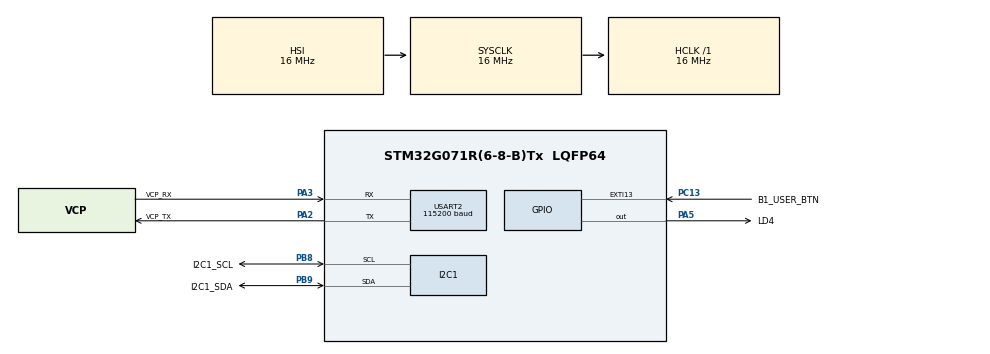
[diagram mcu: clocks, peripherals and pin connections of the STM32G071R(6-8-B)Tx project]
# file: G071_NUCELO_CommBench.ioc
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I2C1.Timing=0x00503D58
Mcu.Family=STM32G0
Mcu.Name=STM32G071R(6-8-B)Tx
Mcu.Package=LQFP64
NVIC.EXTI4_15_IRQn=true\:0\:0\:true\:false\:true\:true\:true\:true
NVIC.I2C1_IRQn=true\:0\:0\:true\:false\:true\:true\:true\:true
NVIC.TIM6_DAC_LPTIM1_IRQn=true\:0\:0\:true\:false\:true\:true\:true\:true
NVIC.USART2_IRQn=true\:0\:0\:true\:false\:true\:true\:true\:true
PA2.GPIO_Label=VCP_TX
PA2.Mode=Asynchronous
PA2.Signal=USART2_TX
PA3.GPIO_Label=VCP_RX
PA3.Mode=Asynchronous
PA3.Signal=USART2_RX
PA5.GPIO_Label=LD4
PA5.Signal=GPIO_Output
PB8.GPIO_Label=I2C1_SCL
PB8.Mode=I2C
PB8.Signal=I2C1_SCL
PB9.GPIO_Label=I2C1_SDA
PB9.Mode=I2C
PB9.Signal=I2C1_SDA
PC13.GPIO_Label=B1_USER_BTN
PC13.GPIO_ModeDefaultEXTI=GPIO_MODE_IT_FALLING
PC13.GPIO_PuPd=GPIO_NOPULL
PC13.Signal=GPXTI13
ProjectManager.HeapSize=0x2000
ProjectManager.StackSize=0x1000
ProjectManager.TargetToolchain=STM32CubeIDE
RCC.AHBFreq_Value=16000000
RCC.CortexFreq_Value=16000000
RCC.EXTERNAL_CLOCK_VALUE=48000
RCC.HCLKFreq_Value=16000000
RCC.HSE_VALUE=8000000
RCC.HSI_VALUE=16000000
RCC.LSE_VALUE=32768
RCC.SYSCLKFreq_VALUE=16000000
RCC.VCOOutputFreq_Value=128000000
TIM6.Period=99
TIM6.Prescaler=15
USART2.BaudRate=115200
USART2.VirtualMode-Asynchronous=VM_ASYNC
USART2.WordLength=WORDLENGTH_8B
VP_TIM6_VS_ClockSourceINT.Mode=Enable_Timer
board=custom

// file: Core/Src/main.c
/* USER CODE BEGIN Header */
/**
  ******************************************************************************
  * @file           : main.c
  * @brief          : Main program body
  ******************************************************************************
  * @attention
  *
  * Copyright (c) 2026 STMicroelectronics.
  * All rights reserved.
  *
  * This software is licensed under terms that can be found in the LICENSE file
  * in the root directory of this software component.
  * If no LICENSE file comes with this software, it is provided AS-IS.
  *
  ******************************************************************************
  */
/* USER CODE END Header */
#include "main.h"

/* USER CODE BEGIN Includes */
#include "global_includes.h"
/* USER CODE END Includes */

I2C_HandleTypeDef hi2c1;

TIM_HandleTypeDef htim6;

UART_HandleTypeDef huart2;

void SystemClock_Config(void);
static void MX_GPIO_Init(void);
static void MX_I2C1_Init(void);
static void MX_USART2_UART_Init(void);
static void MX_TIM6_Init(void);

int main(void)
{

  /* MCU Configuration--------------------------------------------------------*/

  /* Reset of all peripherals, Initializes the Flash interface and the Systick. */
  HAL_Init();

  /* Configure the system clock */
  SystemClock_Config();

  /* Initialize all configured peripherals */
  MX_GPIO_Init();
  MX_I2C1_Init();
  MX_USART2_UART_Init();
  MX_TIM6_Init();
  /* USER CODE BEGIN 2 */
  once();
  /* USER CODE END 2 */

  /* Infinite loop */
  /* USER CODE BEGIN WHILE */
  while (1)
  {
    loop();
    /* USER CODE END WHILE */

  }
}

void SystemClock_Config(void)
{
  RCC_OscInitTypeDef RCC_OscInitStruct = {0};
  RCC_ClkInitTypeDef RCC_ClkInitStruct = {0};

  /** Configure the main internal regulator output voltage
  */
  HAL_PWREx_ControlVoltageScaling(PWR_REGULATOR_VOLTAGE_SCALE1);

  /** Initializes the RCC Oscillators according to the specified parameters
  * in the RCC_OscInitTypeDef structure.
  */
  RCC_OscInitStruct.OscillatorType = RCC_OSCILLATORTYPE_HSI;
  RCC_OscInitStruct.HSIState = RCC_HSI_ON;
  RCC_OscInitStruct.HSIDiv = RCC_HSI_DIV1;
  RCC_OscInitStruct.HSICalibrationValue = RCC_HSICALIBRATION_DEFAULT;
  RCC_OscInitStruct.PLL.PLLState = RCC_PLL_NONE;
  if (HAL_RCC_OscConfig(&RCC_OscInitStruct) != HAL_OK)
  {
    Error_Handler();
  }

  /** Initializes the CPU, AHB and APB buses clocks
  */
  RCC_ClkInitStruct.ClockType = RCC_CLOCKTYPE_HCLK|RCC_CLOCKTYPE_SYSCLK
                              |RCC_CLOCKTYPE_PCLK1;
  RCC_ClkInitStruct.SYSCLKSource = RCC_SYSCLKSOURCE_HSI;
  RCC_ClkInitStruct.AHBCLKDivider = RCC_SYSCLK_DIV1;
  RCC_ClkInitStruct.APB1CLKDivider = RCC_HCLK_DIV1;

  if (HAL_RCC_ClockConfig(&RCC_ClkInitStruct, FLASH_LATENCY_0) != HAL_OK)
  {
    Error_Handler();
  }
}

static void MX_I2C1_Init(void)
{

  hi2c1.Instance = I2C1;
  hi2c1.Init.Timing = 0x00503D58;
  hi2c1.Init.OwnAddress1 = 0;
  hi2c1.Init.AddressingMode = I2C_ADDRESSINGMODE_7BIT;
  hi2c1.Init.DualAddressMode = I2C_DUALADDRESS_DISABLE;
  hi2c1.Init.OwnAddress2 = 0;
  hi2c1.Init.OwnAddress2Masks = I2C_OA2_NOMASK;
  hi2c1.Init.GeneralCallMode = I2C_GENERALCALL_DISABLE;
  hi2c1.Init.NoStretchMode = I2C_NOSTRETCH_DISABLE;
  if (HAL_I2C_Init(&hi2c1) != HAL_OK)
  {
    Error_Handler();
  }

  /** Configure Analogue filter
  */
  if (HAL_I2CEx_ConfigAnalogFilter(&hi2c1, I2C_ANALOGFILTER_ENABLE) != HAL_OK)
  {
    Error_Handler();
  }

  /** Configure Digital filter
  */
  if (HAL_I2CEx_ConfigDigitalFilter(&hi2c1, 0) != HAL_OK)
  {
    Error_Handler();
  }

}

static void MX_TIM6_Init(void)
{

  TIM_MasterConfigTypeDef sMasterConfig = {0};

  htim6.Instance = TIM6;
  htim6.Init.Prescaler = 15;
  htim6.Init.CounterMode = TIM_COUNTERMODE_UP;
  htim6.Init.Period = 99;
  htim6.Init.AutoReloadPreload = TIM_AUTORELOAD_PRELOAD_DISABLE;
  if (HAL_TIM_Base_Init(&htim6) != HAL_OK)
  {
    Error_Handler();
  }
  sMasterConfig.MasterOutputTrigger = TIM_TRGO_RESET;
  sMasterConfig.MasterSlaveMode = TIM_MASTERSLAVEMODE_DISABLE;
  if (HAL_TIMEx_MasterConfigSynchronization(&htim6, &sMasterConfig) != HAL_OK)
  {
    Error_Handler();
  }

}

static void MX_USART2_UART_Init(void)
{

  huart2.Instance = USART2;
  huart2.Init.BaudRate = 115200;
  huart2.Init.WordLength = UART_WORDLENGTH_8B;
  huart2.Init.StopBits = UART_STOPBITS_1;
  huart2.Init.Parity = UART_PARITY_NONE;
  huart2.Init.Mode = UART_MODE_TX_RX;
  huart2.Init.HwFlowCtl = UART_HWCONTROL_NONE;
  huart2.Init.OverSampling = UART_OVERSAMPLING_16;
  huart2.Init.OneBitSampling = UART_ONE_BIT_SAMPLE_DISABLE;
  huart2.Init.ClockPrescaler = UART_PRESCALER_DIV1;
  huart2.AdvancedInit.AdvFeatureInit = UART_ADVFEATURE_NO_INIT;
  if (HAL_UART_Init(&huart2) != HAL_OK)
  {
    Error_Handler();
  }
  if (HAL_UARTEx_SetTxFifoThreshold(&huart2, UART_TXFIFO_THRESHOLD_1_8) != HAL_OK)
  {
    Error_Handler();
  }
  if (HAL_UARTEx_SetRxFifoThreshold(&huart2, UART_RXFIFO_THRESHOLD_1_8) != HAL_OK)
  {
    Error_Handler();
  }
  if (HAL_UARTEx_DisableFifoMode(&huart2) != HAL_OK)
  {
    Error_Handler();
  }

}

static void MX_GPIO_Init(void)
{
  GPIO_InitTypeDef GPIO_InitStruct = {0};

  /* GPIO Ports Clock Enable */
  __HAL_RCC_GPIOC_CLK_ENABLE();
  __HAL_RCC_GPIOA_CLK_ENABLE();
  __HAL_RCC_GPIOB_CLK_ENABLE();

  /*Configure GPIO pin Output Level */
  HAL_GPIO_WritePin(LD4_GPIO_Port, LD4_Pin, GPIO_PIN_RESET);

  /*Configure GPIO pin : B1_USER_BTN_Pin */
  GPIO_InitStruct.Pin = B1_USER_BTN_Pin;
  GPIO_InitStruct.Mode = GPIO_MODE_IT_FALLING;
  GPIO_InitStruct.Pull = GPIO_NOPULL;
  HAL_GPIO_Init(B1_USER_BTN_GPIO_Port, &GPIO_InitStruct);

  /*Configure GPIO pin : LD4_Pin */
  GPIO_InitStruct.Pin = LD4_Pin;
  GPIO_InitStruct.Mode = GPIO_MODE_OUTPUT_PP;
  GPIO_InitStruct.Pull = GPIO_NOPULL;
  GPIO_InitStruct.Speed = GPIO_SPEED_FREQ_LOW;
  HAL_GPIO_Init(LD4_GPIO_Port, &GPIO_InitStruct);

  /* EXTI interrupt init*/
  HAL_NVIC_SetPriority(EXTI4_15_IRQn, 0, 0);
  HAL_NVIC_EnableIRQ(EXTI4_15_IRQn);

}

void Error_Handler(void)
{
  __disable_irq();
  while (1)
  {
  }
}
